AUTOSAR XML (schema 4-0-3)
standard types defined: Boolean
package /AUTOSAR_Platform/DataConstrs
  range DC_Boolean: raw 0..1
package /PATAC/MSM/ComponentTypes
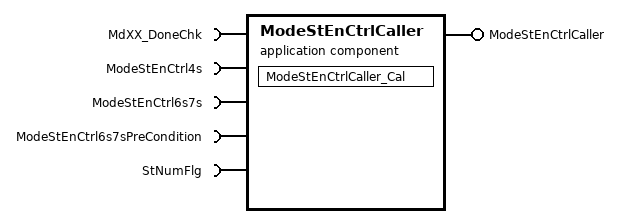
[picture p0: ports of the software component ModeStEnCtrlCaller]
  application sw component type ModeStEnCtrlCaller
    provide port ModeStEnCtrlCaller: server-com-spec{operation=ModeStEnCtrlCaller/Cal, queue-length=1}, provided-interface=ModeStEnCtrlCaller
    5 x require port:
      MdXX_DoneChk: client-com-spec=MdXX_DoneChk/Cal, required-interface=MdXX_DoneChk
      ModeStEnCtrl4s: client-com-spec=ModeStEnCtrl4s/Cal, required-interface=ModeStEnCtrl4s
      ModeStEnCtrl6s7s: client-com-spec=ModeStEnCtrl6s7s/Cal, required-interface=ModeStEnCtrl6s7s
      ModeStEnCtrl6s7sPreCondition: client-com-spec=ModeStEnCtrl6s7sPreCondition/Cal, required-interface=ModeStEnCtrl6s7sPreCondition
      StNumFlg: required-interface=StNumFlg
        required-com-specs:
          data-element=Is4s, filter=data-filter-type=ALWAYS, init-value=0
          data-element=Is6s, filter=data-filter-type=ALWAYS, init-value=0
          data-element=Is6s7s, filter=data-filter-type=ALWAYS, init-value=0
          data-element=Is7s, filter=data-filter-type=ALWAYS, init-value=0
    behavior ModeStEnCtrlCaller_InternalBehavior
      operation invoked event OIT_ModeStEnCtrlCaller_Cal_ModeStEnCtrlCaller_Cal: start-on-event=ModeStEnCtrlCaller_Cal, operation=ModeStEnCtrlCaller.Cal
      runnable ModeStEnCtrlCaller_Cal
        data-receive-point-by-arguments:
          4 x access:
            REC_StNumFlg_Is4s: accessed-variable=StNumFlg.Is4s
            REC_StNumFlg_Is6s: accessed-variable=StNumFlg.Is6s
            REC_StNumFlg_Is6s7s: accessed-variable=StNumFlg.Is6s7s
            REC_StNumFlg_Is7s: accessed-variable=StNumFlg.Is7s
        4 x sync call, all with timeout=0:
          SC_MdXX_DoneChk_Cal: operation=MdXX_DoneChk.Cal
          SC_ModeStEnCtrl4s_Cal: operation=ModeStEnCtrl4s.Cal
          SC_ModeStEnCtrl6s7s_Cal: operation=ModeStEnCtrl6s7s.Cal
          SC_ModeStEnCtrl6s7sPreCondition_Cal: operation=ModeStEnCtrl6s7sPreCondition.Cal
  swc implementation ModeStEnCtrlCaller_Implementation: behavior=ModeStEnCtrlCaller_InternalBehavior
    code-descriptors:
      code Default: artifact-descriptors=autosar-engineering-object={short-label=Default, category=SWSRC}
package /PATAC/MSM/ModeAdjust/PortInterface
  5 x client server interface:
    MdXX_DoneChk
      operation Cal
    ModeStEnCtrl4s
      operation Cal
    ModeStEnCtrl6s7s
      operation Cal
    ModeStEnCtrl6s7sPreCondition
      operation Cal
    ModeStEnCtrlCaller
      operation Cal
  sender receiver interface StNumFlg
    4 x data, all with type=Boolean:
      Is4s
      Is6s
      Is6s7s
      Is7s
    invalidation-policys:
      data-element=Is7s, handle-invalid=DONT-INVALIDATE
      data-element=Is6s, handle-invalid=DONT-INVALIDATE
      data-element=Is4s, handle-invalid=DONT-INVALIDATE
      data-element=Is6s7s, handle-invalid=DONT-INVALIDATE
